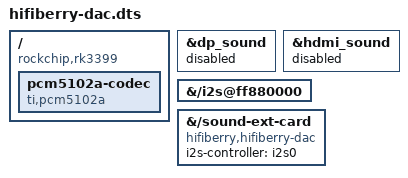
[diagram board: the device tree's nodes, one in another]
/dts-v1/;
/plugin/;

/ {
	compatible = "rockchip,rk3399";

	fragment@0 {
		target = <&dp_sound>;
		__overlay__ {
			status = "disabled";
		};
	};

	fragment@1 {
		target = <&hdmi_sound>;
		__overlay__ {
			status = "disabled";
		};
	};

	fragment@2 {
		target-path = "/";
		__overlay__ {
			pcm5102a-codec {
				#sound-dai-cells = <0>;
				compatible = "ti,pcm5102a";
				status = "okay";
			};
		};
	};

	fragment@3 {
		target-path ="/i2s@ff880000";
		__overlay__ {
			#sound-dai-cells = <0>;
			status = "okay";
		};
	};

	fragment@4 {
		target-path = "/sound-ext-card";
		__overlay__ {
			compatible = "hifiberry,hifiberry-dac";
			i2s-controller = <&i2s0>;
			status = "okay";
		};
	};
};
